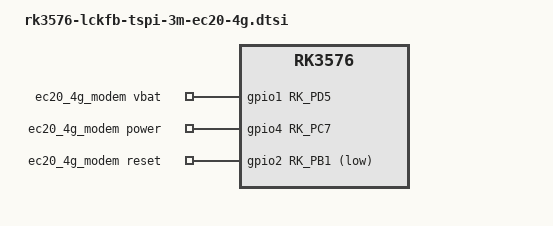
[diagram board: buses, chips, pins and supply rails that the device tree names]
/********************************************************************
 * SPDX-License-Identifier: (GPL-2.0+ OR MIT)
 * 
 * Copyright (c) 2023 Rockchip Electronics Co., Ltd.
 * Copyright (c) 2026 LCKFB <lckfb@sz-jlc.com>
 *********************************************************************
 * Wiki-(Chinese)：https://wiki.lckfb.com/
 * Wiki-(English)：https://wiki.lckfb.com/en/
 *********************************************************************/

/ {
	ec20_4g_modem: ec20-4g-modem {
		compatible="4g-modem-platdata";
		pinctrl-names = "default";
		pinctrl-0 = <&lte_vbat &lte_power_en &lte_reset>;
		4G,vbat-gpio =  <&gpio1 RK_PD5 GPIO_ACTIVE_HIGH>;
		4G,power-gpio = <&gpio4 RK_PC7 GPIO_ACTIVE_HIGH>;
		4G,reset-gpio = <&gpio2 RK_PB1 GPIO_ACTIVE_LOW>;
		status = "okay";
	};

};


&pinctrl {
	ec20_4g_modem {
		lte_vbat: lte_vbat{
			rockchip,pins = <1 RK_PD5 RK_FUNC_GPIO &pcfg_pull_down>;
		};

		lte_power_en: lte_power_en{
			rockchip,pins = <4 RK_PC7 RK_FUNC_GPIO &pcfg_pull_down>;
		};

		lte_reset: lte_reset{
			rockchip,pins = <2 RK_PB1 RK_FUNC_GPIO &pcfg_pull_down>;
		};
    };
};

